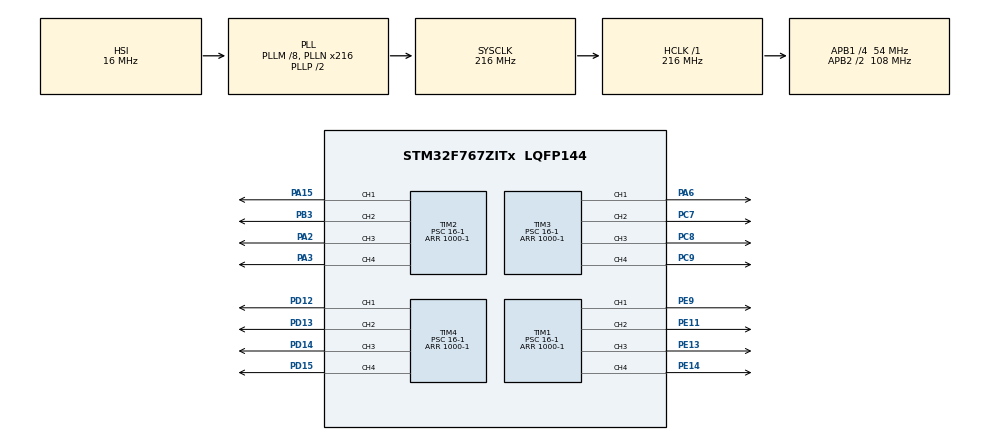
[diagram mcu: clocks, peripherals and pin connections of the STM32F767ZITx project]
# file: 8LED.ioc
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Mcu.Family=STM32F7
Mcu.Name=STM32F767ZITx
Mcu.Package=LQFP144
NVIC.PriorityGroup=NVIC_PRIORITYGROUP_4
PA15.Signal=S_TIM2_CH1_ETR
PA2.Signal=S_TIM2_CH3
PA3.Signal=S_TIM2_CH4
PA6.Signal=S_TIM3_CH1
PB3.Signal=S_TIM2_CH2
PC7.Signal=S_TIM3_CH2
PC8.Signal=S_TIM3_CH3
PC9.Signal=S_TIM3_CH4
PD12.Signal=S_TIM4_CH1
PD13.Signal=S_TIM4_CH2
PD14.Signal=S_TIM4_CH3
PD15.Signal=S_TIM4_CH4
PE11.Signal=S_TIM1_CH2
PE13.Signal=S_TIM1_CH3
PE14.Signal=S_TIM1_CH4
PE9.Signal=S_TIM1_CH1
ProjectManager.HeapSize=0x200
ProjectManager.StackSize=0x400
ProjectManager.TargetToolchain=MDK-ARM V5
RCC.AHBFreq_Value=216000000
RCC.APB1CLKDivider=RCC_HCLK_DIV4
RCC.APB1Freq_Value=54000000
RCC.APB1TimFreq_Value=108000000
RCC.APB2CLKDivider=RCC_HCLK_DIV2
RCC.APB2Freq_Value=108000000
RCC.APB2TimFreq_Value=216000000
RCC.CortexFreq_Value=216000000
RCC.HCLKFreq_Value=216000000
RCC.HSE_VALUE=25000000
RCC.HSI_VALUE=16000000
RCC.LSE_VALUE=32768
RCC.PLLM=8
RCC.PLLN=216
RCC.SYSCLKFreq_VALUE=216000000
RCC.SYSCLKSource=RCC_SYSCLKSOURCE_PLLCLK
RCC.USBFreq_Value=216000000
RCC.VCOOutputFreq_Value=432000000
SH.S_TIM1_CH1.0=TIM1_CH1,PWM Generation1 CH1
SH.S_TIM1_CH2.0=TIM1_CH2,PWM Generation2 CH2
SH.S_TIM1_CH3.0=TIM1_CH3,PWM Generation3 CH3
SH.S_TIM1_CH4.0=TIM1_CH4,PWM Generation4 CH4
SH.S_TIM2_CH1_ETR.0=TIM2_CH1,PWM Generation1 CH1
SH.S_TIM2_CH2.0=TIM2_CH2,PWM Generation2 CH2
SH.S_TIM2_CH3.0=TIM2_CH3,PWM Generation3 CH3
SH.S_TIM2_CH4.0=TIM2_CH4,PWM Generation4 CH4
SH.S_TIM3_CH1.0=TIM3_CH1,PWM Generation1 CH1
SH.S_TIM3_CH2.0=TIM3_CH2,PWM Generation2 CH2
SH.S_TIM3_CH3.0=TIM3_CH3,PWM Generation3 CH3
SH.S_TIM3_CH4.0=TIM3_CH4,PWM Generation4 CH4
SH.S_TIM4_CH1.0=TIM4_CH1,PWM Generation1 CH1
SH.S_TIM4_CH2.0=TIM4_CH2,PWM Generation2 CH2
SH.S_TIM4_CH3.0=TIM4_CH3,PWM Generation3 CH3
SH.S_TIM4_CH4.0=TIM4_CH4,PWM Generation4 CH4
TIM1.Channel-PWM\ Generation1\ CH1=TIM_CHANNEL_1
TIM1.Channel-PWM\ Generation2\ CH2=TIM_CHANNEL_2
TIM1.Channel-PWM\ Generation3\ CH3=TIM_CHANNEL_3
TIM1.Channel-PWM\ Generation4\ CH4=TIM_CHANNEL_4
TIM1.Period=1000-1
TIM1.Prescaler=16-1
TIM1.Pulse-PWM\ Generation1\ CH1=1000/10-1
TIM1.Pulse-PWM\ Generation2\ CH2=1000/10-1
TIM1.Pulse-PWM\ Generation3\ CH3=1000/10-1
TIM1.Pulse-PWM\ Generation4\ CH4=1000/10-1
TIM2.Channel-PWM\ Generation1\ CH1=TIM_CHANNEL_1
TIM2.Channel-PWM\ Generation2\ CH2=TIM_CHANNEL_2
TIM2.Channel-PWM\ Generation3\ CH3=TIM_CHANNEL_3
TIM2.Channel-PWM\ Generation4\ CH4=TIM_CHANNEL_4
TIM2.Period=1000-1
TIM2.Prescaler=16-1
TIM2.Pulse-PWM\ Generation1\ CH1=1000/10-1
TIM2.Pulse-PWM\ Generation2\ CH2=1000/10-1
TIM2.Pulse-PWM\ Generation3\ CH3=1000/10-1
TIM2.Pulse-PWM\ Generation4\ CH4=1000/10-1
TIM3.Channel-PWM\ Generation1\ CH1=TIM_CHANNEL_1
TIM3.Channel-PWM\ Generation2\ CH2=TIM_CHANNEL_2
TIM3.Channel-PWM\ Generation3\ CH3=TIM_CHANNEL_3
TIM3.Channel-PWM\ Generation4\ CH4=TIM_CHANNEL_4
TIM3.Period=1000-1
TIM3.Prescaler=16-1
TIM3.Pulse-PWM\ Generation1\ CH1=1000/10-1
TIM3.Pulse-PWM\ Generation2\ CH2=1000/10-1
TIM3.Pulse-PWM\ Generation3\ CH3=1000/10-1
TIM3.Pulse-PWM\ Generation4\ CH4=1000/10-1
TIM4.Channel-PWM\ Generation1\ CH1=TIM_CHANNEL_1
TIM4.Channel-PWM\ Generation2\ CH2=TIM_CHANNEL_2
TIM4.Channel-PWM\ Generation3\ CH3=TIM_CHANNEL_3
TIM4.Channel-PWM\ Generation4\ CH4=TIM_CHANNEL_4
TIM4.Period=1000-1
TIM4.Prescaler=16-1
TIM4.Pulse-PWM\ Generation1\ CH1=1000/10-1
TIM4.Pulse-PWM\ Generation2\ CH2=1000/10-1
TIM4.Pulse-PWM\ Generation3\ CH3=1000/10-1
TIM4.Pulse-PWM\ Generation4\ CH4=1000/10-1
board=custom

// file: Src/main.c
/* USER CODE BEGIN Header */
/**
  ******************************************************************************
  * @file           : main.c
  * @brief          : Main program body
  ******************************************************************************
  * @attention
  *
  * <h2><center>&copy; Copyright (c) 2020 STMicroelectronics.
  * All rights reserved.</center></h2>
  *
  * This software component is licensed by ST under BSD 3-Clause license,
  * the "License"; You may not use this file except in compliance with the
  * License. You may obtain a copy of the License at:
  *                        opensource.org/licenses/BSD-3-Clause
  *
  ******************************************************************************
  */
/* USER CODE END Header */

#include "main.h"
#include "tim.h"
#include "gpio.h"

/* USER CODE BEGIN PV */
double dutyCycle[16] = {1.0,1.0,1.0,1.0,
											 1.0,1.0,1.0,1.0,
											 1.0,1.0,1.0,1.0,
											 1.0,1.0,1.0,1.0};
double dutyPingpong[2] = {0.5,0.0};
int state = 0;
/* USER CODE END PV */

void SystemClock_Config(void);

/* USER CODE BEGIN 0 */
void showDimmingLED(){
	for(int i = 0; i < 1; i++){
				if(state == 0)
					dutyCycle[i] -= 0.01;
				else if (state == 1)
					dutyCycle[i] += 0.01;

				if(dutyCycle[i] >= 1.05)
				{
					state = 0;
				}
				else if(dutyCycle[i] <= 0.00)
				{
					state = 1;
				}
			}
			htim1.Instance -> CCR1 = (1000-1) * dutyCycle[0];
			htim1.Instance -> CCR2 = (1000-1) * dutyCycle[0];
			htim1.Instance -> CCR3 = (1000-1) * dutyCycle[0];
			htim1.Instance -> CCR4 = (1000-1) * dutyCycle[0];
			htim2.Instance -> CCR1 = (1000-1) * dutyCycle[0];
			htim2.Instance -> CCR2 = (1000-1) * dutyCycle[0];
			htim2.Instance -> CCR3 = (1000-1) * dutyCycle[0];
			htim2.Instance -> CCR4 = (1000-1) * dutyCycle[0];
			htim3.Instance -> CCR1 = (1000-1) * dutyCycle[0];
			htim3.Instance -> CCR2 = (1000-1) * dutyCycle[0];
			htim3.Instance -> CCR3 = (1000-1) * dutyCycle[0];
			htim3.Instance -> CCR4 = (1000-1) * dutyCycle[0];
			htim4.Instance -> CCR1 = (1000-1) * dutyCycle[0];
			htim4.Instance -> CCR2 = (1000-1) * dutyCycle[0];
			htim4.Instance -> CCR3 = (1000-1) * dutyCycle[0];
			htim4.Instance -> CCR4 = (1000-1) * dutyCycle[0];

			HAL_TIM_PWM_Stop(&htim1, TIM_CHANNEL_1);

			HAL_TIM_PWM_Start(&htim1, TIM_CHANNEL_1);

			HAL_TIM_PWM_Stop(&htim1, TIM_CHANNEL_2);

			HAL_TIM_PWM_Start(&htim1, TIM_CHANNEL_2);

			HAL_TIM_PWM_Stop(&htim1, TIM_CHANNEL_3);

			HAL_TIM_PWM_Start(&htim1, TIM_CHANNEL_3);

			HAL_TIM_PWM_Stop(&htim1, TIM_CHANNEL_4);

			HAL_TIM_PWM_Start(&htim1, TIM_CHANNEL_4);

			HAL_TIM_PWM_Stop(&htim2, TIM_CHANNEL_1);
			HAL_TIM_PWM_Start(&htim2, TIM_CHANNEL_1);
			HAL_TIM_PWM_Stop(&htim2, TIM_CHANNEL_2);
			HAL_TIM_PWM_Start(&htim2, TIM_CHANNEL_2);
			HAL_TIM_PWM_Stop(&htim2, TIM_CHANNEL_3);
			HAL_TIM_PWM_Start(&htim2, TIM_CHANNEL_3);
			HAL_TIM_PWM_Stop(&htim2, TIM_CHANNEL_4);
			HAL_TIM_PWM_Start(&htim2, TIM_CHANNEL_4);

			HAL_TIM_PWM_Stop(&htim3, TIM_CHANNEL_1);

			HAL_TIM_PWM_Start(&htim3, TIM_CHANNEL_1);

			HAL_TIM_PWM_Stop(&htim3, TIM_CHANNEL_2);

			HAL_TIM_PWM_Start(&htim3, TIM_CHANNEL_2);

			HAL_TIM_PWM_Stop(&htim3, TIM_CHANNEL_3);

			HAL_TIM_PWM_Start(&htim3, TIM_CHANNEL_3);

			HAL_TIM_PWM_Stop(&htim3, TIM_CHANNEL_4);

			HAL_TIM_PWM_Start(&htim3, TIM_CHANNEL_4);

			HAL_TIM_PWM_Stop(&htim4, TIM_CHANNEL_1);
			HAL_TIM_PWM_Start(&htim4, TIM_CHANNEL_1);
			HAL_TIM_PWM_Stop(&htim4, TIM_CHANNEL_2);
			HAL_TIM_PWM_Start(&htim4, TIM_CHANNEL_2);
			HAL_TIM_PWM_Stop(&htim4, TIM_CHANNEL_3);
			HAL_TIM_PWM_Start(&htim4, TIM_CHANNEL_3);
			HAL_TIM_PWM_Stop(&htim4, TIM_CHANNEL_4);
			HAL_TIM_PWM_Start(&htim4, TIM_CHANNEL_4);

		HAL_Delay(10);
		}
void testLED(){

	for(int i = 0; i < 16; i++){
				if(dutyCycle[i] >= 0.60)
					dutyCycle[i] = 0.00;
				else if(dutyCycle[i] <= 0.01)
					dutyCycle[i] = 1.00;
			}
			htim1.Instance -> CCR1 = (1000-1) * dutyCycle[0];
			htim1.Instance -> CCR2 = (1000-1) * dutyCycle[1];
			htim1.Instance -> CCR3 = (1000-1) * dutyCycle[2];
			htim1.Instance -> CCR4 = (1000-1) * dutyCycle[3];
			htim2.Instance -> CCR1 = (1000-1) * dutyCycle[4];
			htim2.Instance -> CCR2 = (1000-1) * dutyCycle[5];
			htim2.Instance -> CCR3 = (1000-1) * dutyCycle[6];
			htim2.Instance -> CCR4 = (1000-1) * dutyCycle[7];
			htim3.Instance -> CCR1 = (1000-1) * dutyCycle[8];
			htim3.Instance -> CCR2 = (1000-1) * dutyCycle[9];
			htim3.Instance -> CCR3 = (1000-1) * dutyCycle[10];
			htim3.Instance -> CCR4 = (1000-1) * dutyCycle[11];
			htim4.Instance -> CCR1 = (1000-1) * dutyCycle[12];
			htim4.Instance -> CCR2 = (1000-1) * dutyCycle[13];
			htim4.Instance -> CCR3 = (1000-1) * dutyCycle[14];
			htim4.Instance -> CCR4 = (1000-1) * dutyCycle[15];

			HAL_TIM_PWM_Stop(&htim1, TIM_CHANNEL_1);
			HAL_TIM_PWM_Start(&htim1, TIM_CHANNEL_1);
			HAL_TIM_PWM_Stop(&htim1, TIM_CHANNEL_2);
			HAL_TIM_PWM_Start(&htim1, TIM_CHANNEL_2);
			HAL_TIM_PWM_Stop(&htim1, TIM_CHANNEL_3);
			HAL_TIM_PWM_Start(&htim1, TIM_CHANNEL_3);
			HAL_TIM_PWM_Stop(&htim1, TIM_CHANNEL_4);
			HAL_TIM_PWM_Start(&htim1, TIM_CHANNEL_4);

			HAL_TIM_PWM_Stop(&htim2, TIM_CHANNEL_1);
			HAL_TIM_PWM_Start(&htim2, TIM_CHANNEL_1);
			HAL_TIM_PWM_Stop(&htim2, TIM_CHANNEL_2);
			HAL_TIM_PWM_Start(&htim2, TIM_CHANNEL_2);
			HAL_TIM_PWM_Stop(&htim2, TIM_CHANNEL_3);
			HAL_TIM_PWM_Start(&htim2, TIM_CHANNEL_3);
			HAL_TIM_PWM_Stop(&htim2, TIM_CHANNEL_4);
			HAL_TIM_PWM_Start(&htim2, TIM_CHANNEL_4);

			HAL_TIM_PWM_Stop(&htim3, TIM_CHANNEL_1);
			HAL_TIM_PWM_Start(&htim3, TIM_CHANNEL_1);
			HAL_TIM_PWM_Stop(&htim3, TIM_CHANNEL_2);
			HAL_TIM_PWM_Start(&htim3, TIM_CHANNEL_2);
			HAL_TIM_PWM_Stop(&htim3, TIM_CHANNEL_3);
			HAL_TIM_PWM_Start(&htim3, TIM_CHANNEL_3);
			HAL_TIM_PWM_Stop(&htim3, TIM_CHANNEL_4);
			HAL_TIM_PWM_Start(&htim3, TIM_CHANNEL_4);

			HAL_TIM_PWM_Stop(&htim4, TIM_CHANNEL_1);
			HAL_TIM_PWM_Start(&htim4, TIM_CHANNEL_1);
			HAL_TIM_PWM_Stop(&htim4, TIM_CHANNEL_2);
			HAL_TIM_PWM_Start(&htim4, TIM_CHANNEL_2);
			HAL_TIM_PWM_Stop(&htim4, TIM_CHANNEL_3);
			HAL_TIM_PWM_Start(&htim4, TIM_CHANNEL_3);
			HAL_TIM_PWM_Stop(&htim4, TIM_CHANNEL_4);
			HAL_TIM_PWM_Start(&htim4, TIM_CHANNEL_4);

			HAL_Delay(500);
}
void testPingpong(){
			htim1.Instance -> CCR1 = (1000-1) * dutyPingpong[0];
			htim1.Instance -> CCR2 = (1000-1) * dutyPingpong[0];
			htim1.Instance -> CCR3 = (1000-1) * dutyPingpong[0];
			htim1.Instance -> CCR4 = (1000-1) * dutyPingpong[0];
/////////////////////////////
			htim3.Instance -> CCR1 = (1000-1) * dutyPingpong[0];
			htim3.Instance -> CCR2 = (1000-1) * dutyPingpong[0];
			htim3.Instance -> CCR3 = (1000-1) * dutyPingpong[0];
			htim3.Instance -> CCR4 = (1000-1) * dutyPingpong[0];

			HAL_TIM_PWM_Stop(&htim1, TIM_CHANNEL_1);

			HAL_TIM_PWM_Start(&htim1, TIM_CHANNEL_1);

			HAL_TIM_PWM_Stop(&htim1, TIM_CHANNEL_2);

			HAL_TIM_PWM_Start(&htim1, TIM_CHANNEL_2);

					HAL_Delay(50);

			HAL_TIM_PWM_Stop(&htim1, TIM_CHANNEL_3);

			HAL_TIM_PWM_Start(&htim1, TIM_CHANNEL_3);

			HAL_TIM_PWM_Stop(&htim1, TIM_CHANNEL_4);

			HAL_TIM_PWM_Start(&htim1, TIM_CHANNEL_4);
					HAL_Delay(50);

//////////////////////////////////////
			HAL_TIM_PWM_Stop(&htim3, TIM_CHANNEL_1);

			HAL_TIM_PWM_Start(&htim3, TIM_CHANNEL_1);

			HAL_TIM_PWM_Stop(&htim3, TIM_CHANNEL_2);

			HAL_TIM_PWM_Start(&htim3, TIM_CHANNEL_2);
							HAL_Delay(50);

			HAL_TIM_PWM_Stop(&htim3, TIM_CHANNEL_3);

			HAL_TIM_PWM_Start(&htim3, TIM_CHANNEL_3);

			HAL_TIM_PWM_Stop(&htim3, TIM_CHANNEL_4);

			HAL_TIM_PWM_Start(&htim3, TIM_CHANNEL_4);
			HAL_Delay(50);
///////////////////////////////////////
	HAL_TIM_PWM_Stop(&htim1, TIM_CHANNEL_1);
		HAL_TIM_PWM_Stop(&htim1, TIM_CHANNEL_2);
			HAL_TIM_PWM_Stop(&htim1, TIM_CHANNEL_3);
				HAL_TIM_PWM_Stop(&htim1, TIM_CHANNEL_4);
					HAL_TIM_PWM_Stop(&htim3, TIM_CHANNEL_1);
						HAL_TIM_PWM_Stop(&htim3, TIM_CHANNEL_2);
							HAL_TIM_PWM_Stop(&htim3, TIM_CHANNEL_3);
								HAL_TIM_PWM_Stop(&htim3, TIM_CHANNEL_4);
		}

/*USER CODE END 0 */

int main(void)
{

  /* MCU Configuration--------------------------------------------------------*/

  /* Reset of all peripherals, Initializes the Flash interface and the Systick. */
  HAL_Init();

  /* Configure the system clock */
  SystemClock_Config();

  /* Initialize all configured peripherals */
  MX_GPIO_Init();
  MX_TIM1_Init();
  MX_TIM2_Init();
  MX_TIM3_Init();
  MX_TIM4_Init();

  /* Infinite loop */
  while (1)
  {

    /* USER CODE BEGIN 3 */
		//testLED();
		//showDimmingLED();
		testPingpong();
  }
  /* USER CODE END 3 */
}

void SystemClock_Config(void)
{
  RCC_OscInitTypeDef RCC_OscInitStruct = {0};
  RCC_ClkInitTypeDef RCC_ClkInitStruct = {0};

  /** Configure the main internal regulator output voltage
  */
  __HAL_RCC_PWR_CLK_ENABLE();
  __HAL_PWR_VOLTAGESCALING_CONFIG(PWR_REGULATOR_VOLTAGE_SCALE1);
  /** Initializes the CPU, AHB and APB busses clocks
  */
  RCC_OscInitStruct.OscillatorType = RCC_OSCILLATORTYPE_HSI;
  RCC_OscInitStruct.HSIState = RCC_HSI_ON;
  RCC_OscInitStruct.HSICalibrationValue = RCC_HSICALIBRATION_DEFAULT;
  RCC_OscInitStruct.PLL.PLLState = RCC_PLL_ON;
  RCC_OscInitStruct.PLL.PLLSource = RCC_PLLSOURCE_HSI;
  RCC_OscInitStruct.PLL.PLLM = 8;
  RCC_OscInitStruct.PLL.PLLN = 216;
  RCC_OscInitStruct.PLL.PLLP = RCC_PLLP_DIV2;
  RCC_OscInitStruct.PLL.PLLQ = 2;
  if (HAL_RCC_OscConfig(&RCC_OscInitStruct) != HAL_OK)
  {
    Error_Handler();
  }
  /** Activate the Over-Drive mode
  */
  if (HAL_PWREx_EnableOverDrive() != HAL_OK)
  {
    Error_Handler();
  }
  /** Initializes the CPU, AHB and APB busses clocks
  */
  RCC_ClkInitStruct.ClockType = RCC_CLOCKTYPE_HCLK|RCC_CLOCKTYPE_SYSCLK
                              |RCC_CLOCKTYPE_PCLK1|RCC_CLOCKTYPE_PCLK2;
  RCC_ClkInitStruct.SYSCLKSource = RCC_SYSCLKSOURCE_PLLCLK;
  RCC_ClkInitStruct.AHBCLKDivider = RCC_SYSCLK_DIV1;
  RCC_ClkInitStruct.APB1CLKDivider = RCC_HCLK_DIV4;
  RCC_ClkInitStruct.APB2CLKDivider = RCC_HCLK_DIV2;

  if (HAL_RCC_ClockConfig(&RCC_ClkInitStruct, FLASH_LATENCY_7) != HAL_OK)
  {
    Error_Handler();
  }
}

void Error_Handler(void)
{
}

/************************ (C) COPYRIGHT STMicroelectronics *****END OF FILE****/
